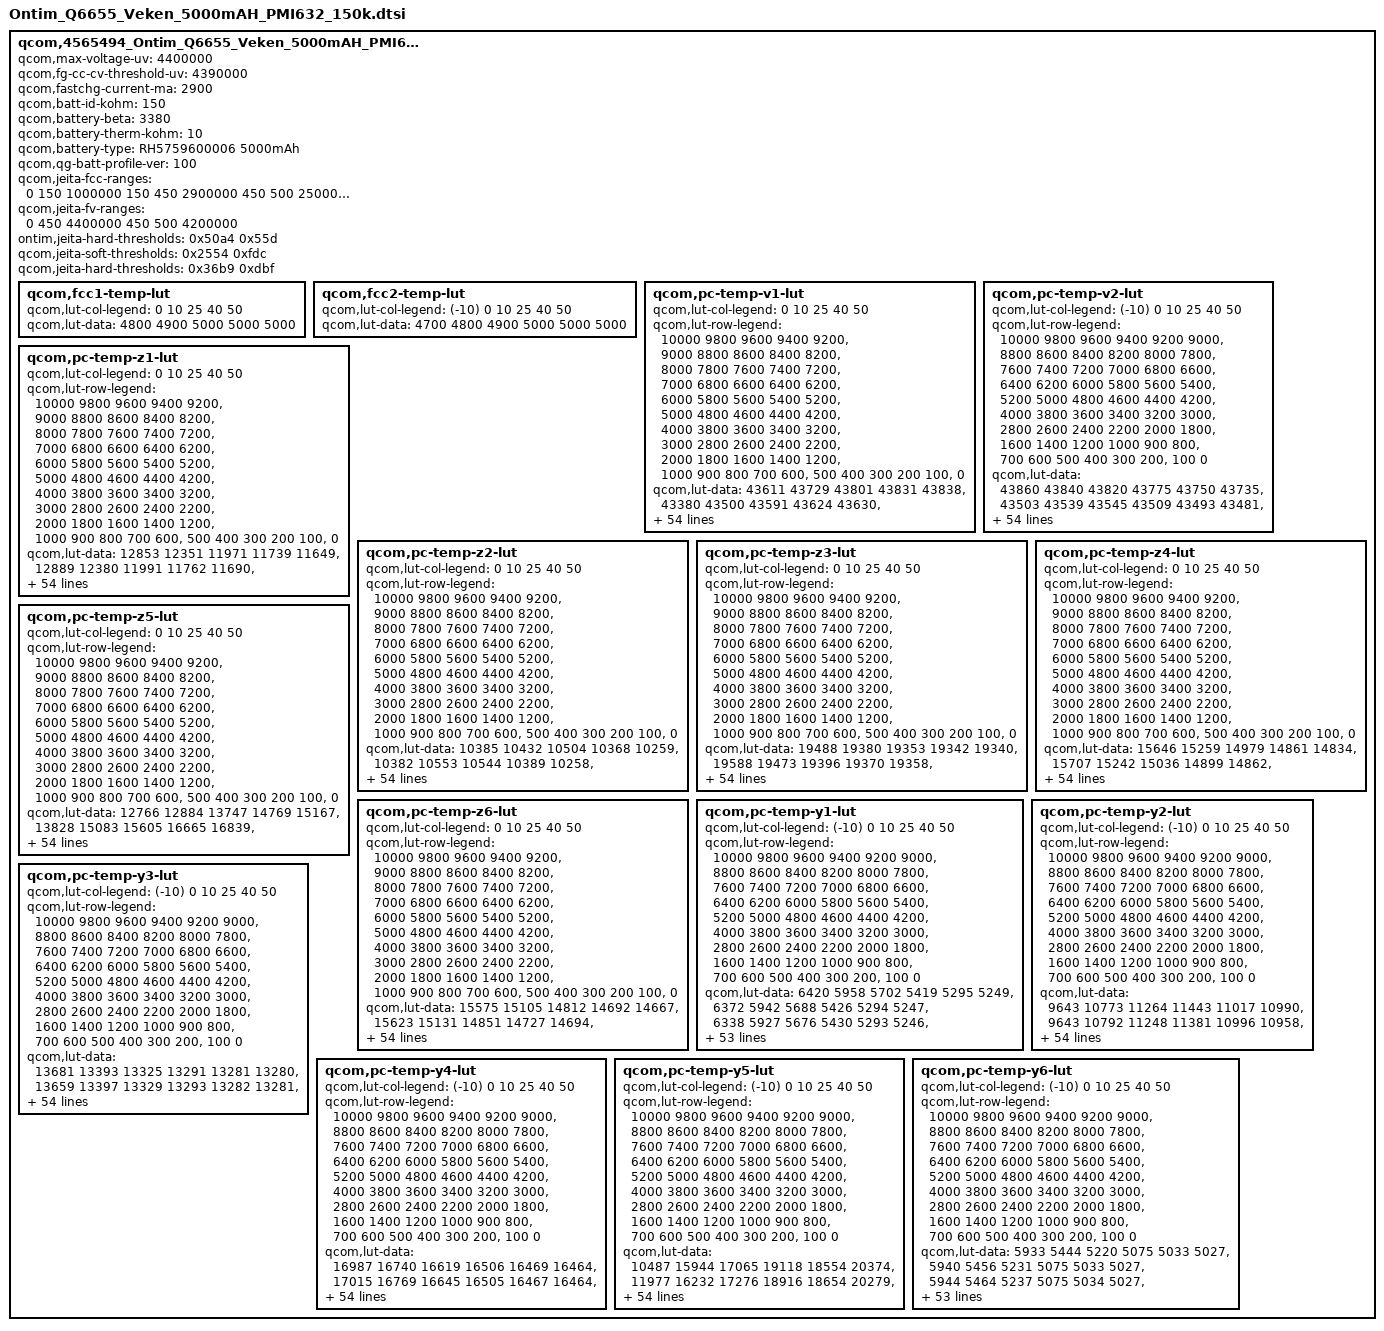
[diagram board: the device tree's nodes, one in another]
qcom,4565494_Ontim_Q6655_Veken_5000mAH_PMI632 {
    /* 4565494_Ontim_Q6655_Veken_5000mAH_PMI632_averaged_MasterSlave_May9th2020 */
    qcom,max-voltage-uv = <4400000>;
    qcom,fg-cc-cv-threshold-uv = <4390000>;
    qcom,fastchg-current-ma = <2900>;
    qcom,batt-id-kohm = <150>;
    qcom,battery-beta = <3380>;
    qcom,battery-therm-kohm = <10>;
    qcom,battery-type = "RH5759600006 5000mAh";
    qcom,qg-batt-profile-ver = <100>;

	qcom,jeita-fcc-ranges = <0     150   1000000
							 150   450   2900000
							 450   500   2500000>;
	
	qcom,jeita-fv-ranges = <0    450   4400000
							450  500   4200000>;

	/* ontim config jeita for dual 85 test begin */
	/* COLD = -20 DegC, HOT = 85 DegC */
	ontim,jeita-hard-thresholds = <0x50a4 0x55d>;
	/* ontim config jeita for dual 85 test end */

	/* COOL = 15 DegC, WARM = 45 DegC */
	qcom,jeita-soft-thresholds = <0x2554 0xfdc>;
	/* COLD = 0 DegC, HOT = 50 DegC */
	qcom,jeita-hard-thresholds = <0x36b9 0xdbf>;

	qcom,fcc1-temp-lut {
		qcom,lut-col-legend = <0 10 25 40 50>;
		qcom,lut-data = <4800 4900 5000 5000 5000>;
	};

	qcom,fcc2-temp-lut {
		qcom,lut-col-legend = <(-10) 0 10 25 40 50>;
		qcom,lut-data = <4700 4800 4900 5000 5000 5000>;
	};

	qcom,pc-temp-v1-lut {
		qcom,lut-col-legend = <0 10 25 40 50>;
		qcom,lut-row-legend = <10000 9800 9600 9400 9200>,
			<9000 8800 8600 8400 8200>,
			<8000 7800 7600 7400 7200>,
			<7000 6800 6600 6400 6200>,
			<6000 5800 5600 5400 5200>,
			<5000 4800 4600 4400 4200>,
			<4000 3800 3600 3400 3200>,
			<3000 2800 2600 2400 2200>,
			<2000 1800 1600 1400 1200>,
			<1000 900 800 700 600>,
			<500 400 300 200 100>,
			<0>;
		qcom,lut-data = <43611 43729 43801 43831 43838>,
			<43380 43500 43591 43624 43630>,
			<43143 43270 43369 43412 43421>,
			<42904 43039 43143 43195 43208>,
			<42669 42807 42911 42970 42984>,
			<42434 42572 42675 42736 42752>,
			<42203 42338 42440 42503 42520>,
			<41978 42105 42203 42265 42286>,
			<41756 41877 41971 42031 42053>,
			<41539 41652 41742 41800 41824>,
			<41325 41434 41517 41572 41596>,
			<41117 41222 41299 41352 41374>,
			<40917 41016 41087 41136 41154>,
			<40723 40818 40883 40928 40942>,
			<40535 40625 40682 40725 40739>,
			<40350 40440 40490 40529 40545>,
			<40173 40262 40308 40343 40358>,
			<40011 40092 40134 40164 40178>,
			<39861 39937 39969 39994 40005>,
			<39714 39789 39824 39843 39849>,
			<39571 39615 39665 39691 39694>,
			<39426 39405 39419 39480 39490>,
			<39257 39193 39119 39191 39212>,
			<39050 38983 38929 38974 38992>,
			<38860 38782 38823 38857 38872>,
			<38710 38661 38737 38765 38778>,
			<38582 38593 38650 38668 38673>,
			<38496 38537 38570 38572 38565>,
			<38438 38477 38492 38481 38469>,
			<38393 38417 38415 38394 38387>,
			<38353 38363 38345 38316 38314>,
			<38319 38312 38282 38247 38243>,
			<38287 38265 38225 38189 38177>,
			<38258 38223 38174 38132 38112>,
			<38231 38185 38131 38079 38051>,
			<38202 38147 38090 38027 37991>,
			<38173 38114 38051 37976 37930>,
			<38136 38076 38011 37926 37870>,
			<38077 38017 37954 37859 37795>,
			<37995 37927 37864 37764 37695>,
			<37896 37824 37758 37654 37583>,
			<37770 37703 37643 37541 37466>,
			<37626 37563 37510 37413 37335>,
			<37458 37394 37345 37252 37167>,
			<37304 37241 37195 37111 37034>,
			<37207 37133 37092 37027 36964>,
			<37165 37103 37065 36996 36934>,
			<37130 37084 37042 36978 36917>,
			<37098 37057 37025 36957 36896>,
			<37055 37017 36986 36912 36843>,
			<36927 36845 36795 36685 36592>,
			<36523 36408 36365 36257 36160>,
			<35952 35824 35794 35689 35593>,
			<35000 35000 35000 35000 35000>, // 2
			<34500 34500 34500 34500 34500>, // 1
			<34000 34000 34000 34000 34000>; // 0
	};

	qcom,pc-temp-v2-lut {
		qcom,lut-col-legend = <(-10) 0 10 25 40 50>;
		qcom,lut-row-legend = <10000 9800 9600 9400 9200 9000>,
			<8800 8600 8400 8200 8000 7800>,
			<7600 7400 7200 7000 6800 6600>,
			<6400 6200 6000 5800 5600 5400>,
			<5200 5000 4800 4600 4400 4200>,
			<4000 3800 3600 3400 3200 3000>,
			<2800 2600 2400 2200 2000 1800>,
			<1600 1400 1200 1000 900 800>,
			<700 600 500 400 300 200>,
			<100 0>;
		qcom,lut-data = <43860 43840 43820 43775 43750 43735>,
			<43503 43539 43545 43509 43493 43481>,
			<43180 43256 43280 43253 43243 43233>,
			<42897 42995 43029 43006 43001 42994>,
			<42652 42753 42791 42771 42769 42763>,
			<42417 42515 42553 42537 42536 42532>,
			<42179 42270 42312 42301 42300 42298>,
			<41943 42026 42070 42064 42065 42063>,
			<41702 41790 41833 41832 41833 41832>,
			<41449 41560 41599 41603 41605 41604>,
			<41218 41335 41371 41379 41380 41379>,
			<41041 41112 41151 41160 41160 41160>,
			<40885 40895 40937 40946 40945 40944>,
			<40679 40698 40731 40740 40739 40738>,
			<40385 40521 40528 40539 40540 40536>,
			<40081 40338 40336 40346 40349 40344>,
			<39819 40138 40166 40162 40165 40161>,
			<39572 39927 39999 39985 39988 39987>,
			<39348 39701 39801 39820 39822 39821>,
			<39142 39453 39575 39672 39672 39670>,
			<38949 39217 39351 39500 39500 39499>,
			<38753 39012 39134 39257 39265 39269>,
			<38565 38824 38930 39001 39019 39026>,
			<38423 38655 38760 38815 38836 38844>,
			<38320 38500 38614 38667 38688 38697>,
			<38237 38361 38484 38541 38562 38570>,
			<38168 38228 38365 38429 38453 38459>,
			<38109 38111 38256 38331 38357 38360>,
			<38054 38035 38155 38242 38268 38269>,
			<38002 37983 38059 38161 38187 38184>,
			<37951 37939 37981 38087 38114 38108>,
			<37899 37896 37919 38015 38048 38043>,
			<37845 37855 37867 37948 37987 37981>,
			<37791 37812 37823 37887 37922 37913>,
			<37738 37767 37787 37832 37856 37839>,
			<37684 37718 37749 37776 37781 37756>,
			<37625 37666 37709 37715 37691 37656>,
			<37562 37609 37666 37652 37595 37548>,
			<37493 37540 37606 37578 37509 37456>,
			<37416 37459 37526 37494 37428 37373>,
			<37332 37363 37429 37403 37341 37287>,
			<37239 37245 37297 37304 37244 37192>,
			<37137 37113 37151 37189 37132 37082>,
			<37039 36976 37000 37044 36989 36934>,
			<36947 36850 36857 36918 36882 36830>,
			<36861 36749 36757 36859 36838 36787>,
			<36818 36707 36716 36845 36829 36777>,
			<36775 36666 36674 36827 36814 36763>,
			<36731 36621 36622 36803 36789 36736>,
			<36678 36551 36534 36744 36718 36656>,
			<36600 36407 36347 36543 36467 36365>,
			<36414 36050 35928 36075 35978 35872>,
			<36011 35414 35293 35463 35347 35233>,
			<35000 35000 35000 35000 35000 35000>, // 2
			<34500 34500 34500 34500 34500 34500>, // 1
			<33000 33000 33000 33000 33000 33000>; // 0
	};

	qcom,pc-temp-z1-lut {
		qcom,lut-col-legend = <0 10 25 40 50>;
		qcom,lut-row-legend = <10000 9800 9600 9400 9200>,
			<9000 8800 8600 8400 8200>,
			<8000 7800 7600 7400 7200>,
			<7000 6800 6600 6400 6200>,
			<6000 5800 5600 5400 5200>,
			<5000 4800 4600 4400 4200>,
			<4000 3800 3600 3400 3200>,
			<3000 2800 2600 2400 2200>,
			<2000 1800 1600 1400 1200>,
			<1000 900 800 700 600>,
			<500 400 300 200 100>,
			<0>;
		qcom,lut-data = <12853 12351 11971 11739 11649>,
			<12889 12380 11991 11762 11690>,
			<12906 12390 12000 11769 11696>,
			<12919 12387 12000 11771 11698>,
			<12917 12384 11997 11768 11699>,
			<12897 12380 11994 11765 11699>,
			<12879 12372 11988 11763 11700>,
			<12873 12364 11981 11761 11701>,
			<12870 12354 11974 11759 11702>,
			<12869 12344 11968 11760 11705>,
			<12869 12338 11963 11761 11708>,
			<12867 12334 11963 11761 11710>,
			<12855 12331 11964 11761 11710>,
			<12834 12329 11964 11762 11710>,
			<12818 12328 11966 11762 11710>,
			<12807 12327 11967 11762 11711>,
			<12799 12321 11968 11763 11712>,
			<12795 12317 11968 11764 11712>,
			<12791 12319 11968 11766 11714>,
			<12789 12323 11971 11767 11715>,
			<12791 12326 11974 11768 11716>,
			<12795 12333 11974 11769 11717>,
			<12795 12338 11974 11770 11718>,
			<12793 12341 11975 11771 11719>,
			<12793 12345 11980 11773 11721>,
			<12801 12346 11986 11777 11724>,
			<12816 12348 11988 11780 11727>,
			<12822 12351 11991 11783 11730>,
			<12815 12357 11993 11786 11733>,
			<12808 12365 11997 11790 11736>,
			<12808 12367 12002 11794 11739>,
			<12810 12364 12006 11797 11743>,
			<12813 12360 12009 11801 11746>,
			<12818 12363 12013 11805 11749>,
			<12825 12373 12016 11809 11752>,
			<12832 12379 12019 11813 11755>,
			<12839 12381 12022 11817 11758>,
			<12847 12383 12026 11820 11761>,
			<12859 12386 12031 11824 11764>,
			<12875 12392 12040 11830 11767>,
			<12890 12401 12049 11835 11771>,
			<12915 12420 12057 11838 11774>,
			<12927 12433 12063 11842 11778>,
			<12921 12435 12065 11847 11781>,
			<12941 12441 12075 11854 11785>,
			<12929 12435 12091 11856 11787>,
			<12954 12443 12085 11855 11786>,
			<12946 12431 12082 11855 11787>,
			<12953 12442 12087 11861 11788>,
			<12946 12434 12082 11863 11793>,
			<12937 12466 12091 11874 11799>,
			<12965 12474 12118 11879 11807>,
			<13009 12477 12124 11890 11815>,
			<12995 12493 12131 11906 11830>,
			<12995 12493 12131 11906 11830>,
			<12995 12493 12131 11906 11830>;
	};

	qcom,pc-temp-z2-lut {
		qcom,lut-col-legend = <0 10 25 40 50>;
		qcom,lut-row-legend = <10000 9800 9600 9400 9200>,
			<9000 8800 8600 8400 8200>,
			<8000 7800 7600 7400 7200>,
			<7000 6800 6600 6400 6200>,
			<6000 5800 5600 5400 5200>,
			<5000 4800 4600 4400 4200>,
			<4000 3800 3600 3400 3200>,
			<3000 2800 2600 2400 2200>,
			<2000 1800 1600 1400 1200>,
			<1000 900 800 700 600>,
			<500 400 300 200 100>,
			<0>;
		qcom,lut-data = <10385 10432 10504 10368 10259>,
			<10382 10553 10544 10389 10258>,
			<10349 10588 10591 10416 10273>,
			<10307 10552 10608 10438 10279>,
			<10274 10503 10583 10427 10285>,
			<10243 10462 10547 10396 10302>,
			<10219 10423 10518 10370 10307>,
			<10201 10396 10488 10347 10280>,
			<10186 10379 10462 10331 10253>,
			<10177 10367 10440 10321 10234>,
			<10169 10358 10423 10309 10194>,
			<10165 10350 10417 10304 10174>,
			<10165 10346 10413 10290 10166>,
			<10167 10356 10414 10280 10163>,
			<10170 10376 10421 10279 10150>,
			<10179 10397 10433 10278 10127>,
			<10192 10425 10448 10277 10127>,
			<10210 10452 10467 10276 10138>,
			<10236 10471 10483 10275 10152>,
			<10263 10490 10493 10263 10173>,
			<10288 10518 10506 10252 10206>,
			<10314 10565 10567 10311 10264>,
			<10337 10596 10678 10511 10379>,
			<10361 10580 10700 10615 10441>,
			<10378 10544 10568 10495 10394>,
			<10387 10527 10452 10345 10328>,
			<10393 10522 10475 10371 10363>,
			<10398 10518 10539 10517 10538>,
			<10404 10524 10580 10583 10626>,
			<10409 10539 10609 10548 10488>,
			<10415 10550 10623 10492 10294>,
			<10421 10556 10615 10437 10201>,
			<10427 10562 10599 10376 10137>,
			<10435 10569 10595 10351 10118>,
			<10443 10577 10596 10346 10143>,
			<10452 10587 10599 10343 10186>,
			<10460 10598 10613 10352 10235>,
			<10470 10611 10642 10383 10297>,
			<10482 10629 10674 10423 10347>,
			<10495 10652 10717 10506 10391>,
			<10508 10665 10744 10570 10418>,
			<10520 10669 10747 10573 10419>,
			<10535 10674 10749 10568 10417>,
			<10555 10689 10750 10584 10497>,
			<10786 10807 10785 10567 10509>,
			<10602 10885 10806 10506 10407>,
			<10590 10891 10779 10506 10383>,
			<10558 10979 10763 10511 10419>,
			<10496 11225 10718 10532 10439>,
			<10451 11321 10744 10632 10538>,
			<10327 11266 10841 10556 10445>,
			<10318 10955 10819 10392 10239>,
			<10115 10811 10708 10328 10172>,
			<9950 10578 10687 10292 10116>,
			<9950 10578 10687 10292 10116>,
			<9950 10578 10687 10292 10116>;
	};

	qcom,pc-temp-z3-lut {
		qcom,lut-col-legend = <0 10 25 40 50>;
		qcom,lut-row-legend = <10000 9800 9600 9400 9200>,
			<9000 8800 8600 8400 8200>,
			<8000 7800 7600 7400 7200>,
			<7000 6800 6600 6400 6200>,
			<6000 5800 5600 5400 5200>,
			<5000 4800 4600 4400 4200>,
			<4000 3800 3600 3400 3200>,
			<3000 2800 2600 2400 2200>,
			<2000 1800 1600 1400 1200>,
			<1000 900 800 700 600>,
			<500 400 300 200 100>,
			<0>;
		qcom,lut-data = <19488 19380 19353 19342 19340>,
			<19588 19473 19396 19370 19358>,
			<19649 19519 19422 19384 19370>,
			<19690 19534 19436 19392 19379>,
			<19707 19542 19444 19400 19388>,
			<19717 19545 19449 19406 19396>,
			<19721 19547 19451 19410 19400>,
			<19719 19548 19451 19414 19402>,
			<19715 19548 19452 19416 19404>,
			<19711 19548 19450 19416 19403>,
			<19708 19546 19448 19414 19401>,
			<19703 19539 19443 19411 19399>,
			<19698 19531 19433 19404 19395>,
			<19693 19525 19427 19398 19391>,
			<19686 19520 19423 19394 19387>,
			<19680 19515 19420 19390 19382>,
			<19672 19509 19417 19386 19378>,
			<19660 19504 19414 19384 19374>,
			<19642 19498 19410 19380 19371>,
			<19632 19491 19405 19373 19366>,
			<19630 19492 19402 19365 19361>,
			<19629 19506 19409 19366 19361>,
			<19632 19518 19425 19377 19365>,
			<19647 19517 19429 19382 19367>,
			<19658 19514 19410 19367 19356>,
			<19658 19511 19393 19348 19342>,
			<19655 19502 19393 19352 19351>,
			<19652 19495 19395 19375 19396>,
			<19648 19495 19399 19392 19419>,
			<19642 19496 19414 19402 19411>,
			<19636 19497 19427 19408 19399>,
			<19630 19500 19429 19406 19391>,
			<19624 19502 19430 19397 19384>,
			<19619 19502 19430 19389 19377>,
			<19614 19500 19424 19382 19369>,
			<19610 19498 19417 19375 19362>,
			<19605 19494 19411 19368 19356>,
			<19600 19489 19404 19361 19351>,
			<19595 19485 19400 19359 19349>,
			<19588 19481 19398 19359 19347>,
			<19581 19476 19396 19358 19346>,
			<19572 19472 19393 19358 19348>,
			<19562 19467 19391 19358 19353>,
			<19550 19460 19387 19358 19360>,
			<19495 19435 19378 19357 19360>,
			<19337 19422 19372 19345 19344>,
			<19325 19408 19367 19344 19342>,
			<19317 19333 19366 19335 19330>,
			<19308 19302 19351 19333 19326>,
			<19302 19293 19346 19325 19318>,
			<19287 19302 19341 19340 19333>,
			<19311 19322 19352 19358 19352>,
			<19322 19319 19350 19356 19349>,
			<19340 19328 19342 19351 19349>,
			<19340 19328 19342 19351 19349>,
			<19340 19328 19342 19351 19349>;
	};

	qcom,pc-temp-z4-lut {
		qcom,lut-col-legend = <0 10 25 40 50>;
		qcom,lut-row-legend = <10000 9800 9600 9400 9200>,
			<9000 8800 8600 8400 8200>,
			<8000 7800 7600 7400 7200>,
			<7000 6800 6600 6400 6200>,
			<6000 5800 5600 5400 5200>,
			<5000 4800 4600 4400 4200>,
			<4000 3800 3600 3400 3200>,
			<3000 2800 2600 2400 2200>,
			<2000 1800 1600 1400 1200>,
			<1000 900 800 700 600>,
			<500 400 300 200 100>,
			<0>;
		qcom,lut-data = <15646 15259 14979 14861 14834>,
			<15707 15242 15036 14899 14862>,
			<15603 15207 14996 14882 14852>,
			<15442 15130 14954 14857 14836>,
			<15325 15037 14911 14835 14819>,
			<15223 14974 14869 14811 14799>,
			<15139 14925 14836 14790 14781>,
			<15074 14885 14809 14770 14765>,
			<15020 14849 14786 14752 14750>,
			<14974 14820 14765 14735 14735>,
			<14933 14798 14748 14721 14721>,
			<14898 14782 14736 14711 14712>,
			<14869 14767 14726 14704 14706>,
			<14843 14752 14719 14699 14701>,
			<14824 14738 14713 14694 14697>,
			<14809 14730 14708 14690 14694>,
			<14797 14725 14703 14686 14690>,
			<14786 14721 14699 14681 14686>,
			<14777 14716 14695 14679 14682>,
			<14768 14710 14691 14677 14678>,
			<14755 14711 14689 14676 14674>,
			<14743 14728 14721 14692 14688>,
			<14745 14753 14798 14765 14762>,
			<14771 14791 14830 14811 14808>,
			<14801 14840 14839 14820 14810>,
			<14825 14853 14842 14825 14810>,
			<14847 14840 14835 14814 14794>,
			<14852 14823 14815 14773 14731>,
			<14844 14808 14794 14739 14695>,
			<14832 14792 14766 14716 14692>,
			<14820 14778 14743 14700 14690>,
			<14808 14764 14729 14693 14686>,
			<14795 14751 14719 14689 14681>,
			<14783 14743 14715 14688 14679>,
			<14772 14736 14713 14688 14678>,
			<14760 14730 14712 14688 14677>,
			<14748 14724 14711 14688 14677>,
			<14737 14719 14709 14688 14678>,
			<14730 14718 14710 14689 14680>,
			<14724 14718 14714 14698 14693>,
			<14719 14717 14718 14706 14703>,
			<14716 14708 14712 14702 14698>,
			<14710 14697 14702 14695 14689>,
			<14700 14690 14697 14694 14691>,
			<14699 14672 14681 14684 14683>,
			<14836 14658 14663 14668 14664>,
			<14845 14662 14656 14662 14658>,
			<14849 14738 14644 14654 14653>,
			<14853 14763 14643 14635 14635>,
			<14853 14769 14641 14630 14626>,
			<14863 14761 14659 14647 14655>,
			<14862 14755 14664 14649 14660>,
			<14870 14766 14670 14656 14668>,
			<14878 14770 14681 14664 14671>,
			<14878 14770 14681 14664 14671>,
			<14878 14770 14681 14664 14671>;
	};

	qcom,pc-temp-z5-lut {
		qcom,lut-col-legend = <0 10 25 40 50>;
		qcom,lut-row-legend = <10000 9800 9600 9400 9200>,
			<9000 8800 8600 8400 8200>,
			<8000 7800 7600 7400 7200>,
			<7000 6800 6600 6400 6200>,
			<6000 5800 5600 5400 5200>,
			<5000 4800 4600 4400 4200>,
			<4000 3800 3600 3400 3200>,
			<3000 2800 2600 2400 2200>,
			<2000 1800 1600 1400 1200>,
			<1000 900 800 700 600>,
			<500 400 300 200 100>,
			<0>;
		qcom,lut-data = <12766 12884 13747 14769 15167>,
			<13828 15083 15605 16665 16839>,
			<14589 16392 16712 17614 17951>,
			<15230 16968 17554 18282 18784>,
			<15818 17397 18208 19022 19886>,
			<16349 17931 18782 19726 21091>,
			<16847 18500 19394 20589 22142>,
			<17312 19176 20008 21711 23102>,
			<17779 20175 20705 22858 24038>,
			<18346 21233 21692 24056 24936>,
			<19096 21892 22473 25198 25815>,
			<19953 22346 22649 25596 26740>,
			<20892 22900 22720 25668 27884>,
			<21928 23955 22891 25774 28652>,
			<22927 25296 23591 26160 28736>,
			<24075 26363 24535 26818 28712>,
			<24949 27273 25408 27720 28966>,
			<25101 28026 26341 29167 30027>,
			<25096 28617 27191 29924 31112>,
			<25151 29368 27801 28884 31877>,
			<26824 32058 28679 27406 32462>,
			<30546 44017 33919 28117 32453>,
			<36678 53303 43780 32062 31728>,
			<50036 50853 45784 34082 30495>,
			<59250 44450 34171 27140 24758>,
			<57985 39345 23247 18414 17715>,
			<54265 33610 21487 17763 18942>,
			<50699 29640 20595 19250 27784>,
			<47025 29334 20685 21346 32314>,
			<43698 29292 23448 25699 31015>,
			<41482 29489 27237 29835 29451>,
			<39719 31551 31098 30828 29490>,
			<38656 34424 35166 31304 30134>,
			<38012 36900 37476 31580 30473>,
			<37607 39530 38964 31852 30465>,
			<37698 41159 39669 32033 30372>,
			<38553 42310 39012 31566 30165>,
			<39578 43096 37446 30281 29708>,
			<40673 42961 36079 29444 29029>,
			<41776 42203 34805 28919 27114>,
			<41731 41410 33502 28314 25578>,
			<38697 39880 32084 27229 25886>,
			<36611 38055 30792 26268 27035>,
			<35798 36418 29780 26979 31392>,
			<29108 35321 30482 27770 32987>,
			<13232 34617 31580 24304 25487>,
			<12816 27912 29518 24010 24230>,
			<12561 14534 31732 22056 20707>,
			<12293 12861 24898 26301 23886>,
			<12179 12558 24635 25720 24665>,
			<12015 12972 20238 27986 25734>,
			<12316 13690 20220 26371 23564>,
			<12309 13272 18716 22106 19316>,
			<12769 13619 16863 18563 17113>,
			<12769 13619 16863 18563 17113>,
			<12769 13619 16863 18563 17113>;
	};

	qcom,pc-temp-z6-lut {
		qcom,lut-col-legend = <0 10 25 40 50>;
		qcom,lut-row-legend = <10000 9800 9600 9400 9200>,
			<9000 8800 8600 8400 8200>,
			<8000 7800 7600 7400 7200>,
			<7000 6800 6600 6400 6200>,
			<6000 5800 5600 5400 5200>,
			<5000 4800 4600 4400 4200>,
			<4000 3800 3600 3400 3200>,
			<3000 2800 2600 2400 2200>,
			<2000 1800 1600 1400 1200>,
			<1000 900 800 700 600>,
			<500 400 300 200 100>,
			<0>;
		qcom,lut-data = <15575 15105 14812 14692 14667>,
			<15623 15131 14851 14727 14694>,
			<15583 15135 14848 14727 14697>,
			<15517 15103 14842 14725 14697>,
			<15462 15054 14827 14720 14696>,
			<15407 15020 14807 14712 14692>,
			<15358 14992 14792 14705 14687>,
			<15319 14968 14778 14699 14682>,
			<15284 14948 14766 14692 14676>,
			<15254 14930 14756 14685 14671>,
			<15226 14914 14746 14679 14665>,
			<15201 14900 14736 14672 14659>,
			<15180 14887 14727 14666 14655>,
			<15160 14875 14720 14660 14650>,
			<15143 14865 14716 14655 14646>,
			<15130 14858 14712 14651 14641>,
			<15117 14852 14708 14647 14637>,
			<15103 14848 14704 14644 14633>,
			<15088 14843 14701 14641 14630>,
			<15078 14838 14698 14636 14625>,
			<15073 14839 14695 14631 14621>,
			<15070 14853 14714 14640 14627>,
			<15072 14872 14757 14678 14661>,
			<15092 14890 14770 14699 14682>,
			<15113 14910 14766 14695 14678>,
			<15125 14914 14760 14689 14672>,
			<15135 14906 14755 14685 14669>,
			<15137 14896 14750 14681 14668>,
			<15132 14890 14746 14678 14665>,
			<15125 14886 14743 14675 14660>,
			<15119 14882 14740 14671 14654>,
			<15111 14878 14737 14667 14649>,
			<15104 14875 14734 14662 14643>,
			<15098 14872 14731 14658 14639>,
			<15094 14870 14729 14654 14634>,
			<15089 14868 14726 14650 14630>,
			<15084 14864 14723 14647 14627>,
			<15081 14862 14719 14643 14624>,
			<15080 14862 14719 14642 14624>,
			<15080 14864 14721 14647 14628>,
			<15080 14864 14723 14650 14633>,
			<15082 14861 14721 14649 14632>,
			<15083 14859 14718 14647 14631>,
			<15083 14857 14716 14647 14635>,
			<15063 14846 14708 14643 14633>,
			<15050 14837 14699 14631 14617>,
			<15049 14833 14694 14628 14613>,
			<15049 14828 14689 14620 14605>,
			<15047 14824 14682 14611 14595>,
			<15049 14826 14680 14605 14587>,
			<15056 14833 14689 14621 14608>,
			<15074 14848 14701 14635 14624>,
			<15095 14860 14707 14639 14628>,
			<15125 14880 14714 14643 14633>,
			<15125 14880 14714 14643 14633>,
			<15125 14880 14714 14643 14633>;
	};

	qcom,pc-temp-y1-lut {
		qcom,lut-col-legend = <(-10) 0 10 25 40 50>;
		qcom,lut-row-legend = <10000 9800 9600 9400 9200 9000>,
			<8800 8600 8400 8200 8000 7800>,
			<7600 7400 7200 7000 6800 6600>,
			<6400 6200 6000 5800 5600 5400>,
			<5200 5000 4800 4600 4400 4200>,
			<4000 3800 3600 3400 3200 3000>,
			<2800 2600 2400 2200 2000 1800>,
			<1600 1400 1200 1000 900 800>,
			<700 600 500 400 300 200>,
			<100 0>;
		qcom,lut-data = <6420 5958 5702 5419 5295 5249>,
			<6372 5942 5688 5426 5294 5247>,
			<6338 5927 5676 5430 5293 5246>,
			<6315 5915 5666 5431 5291 5244>,
			<6303 5907 5659 5431 5290 5242>,
			<6299 5902 5656 5430 5288 5241>,
			<6313 5901 5657 5427 5286 5241>,
			<6336 5903 5660 5423 5284 5240>,
			<6339 5902 5660 5420 5282 5240>,
			<6322 5899 5657 5416 5281 5239>,
			<6307 5897 5656 5414 5280 5238>,
			<6313 5898 5655 5413 5279 5237>,
			<6326 5901 5654 5413 5279 5237>,
			<6330 5904 5652 5413 5278 5237>,
			<6330 5911 5646 5414 5278 5238>,
			<6330 5915 5643 5414 5278 5238>,
			<6325 5911 5650 5414 5278 5239>,
			<6316 5906 5661 5414 5278 5240>,
			<6312 5906 5665 5414 5279 5240>,
			<6307 5911 5666 5415 5280 5241>,
			<6303 5914 5667 5416 5281 5241>,
			<6306 5915 5665 5419 5281 5242>,
			<6311 5916 5662 5422 5282 5242>,
			<6314 5917 5661 5425 5283 5243>,
			<6311 5926 5663 5428 5285 5245>,
			<6307 5932 5665 5431 5287 5246>,
			<6305 5925 5671 5433 5290 5247>,
			<6304 5916 5679 5436 5292 5249>,
			<6303 5914 5678 5440 5295 5251>,
			<6317 5915 5669 5446 5297 5253>,
			<6333 5916 5665 5451 5300 5256>,
			<6331 5922 5674 5454 5303 5258>,
			<6316 5929 5687 5455 5306 5260>,
			<6308 5930 5690 5456 5309 5262>,
			<6321 5928 5690 5458 5311 5264>,
			<6335 5927 5690 5460 5313 5265>,
			<6335 5927 5694 5461 5315 5267>,
			<6330 5928 5698 5462 5316 5269>,
			<6326 5927 5698 5464 5318 5271>,
			<6321 5925 5696 5467 5321 5272>,
			<6316 5924 5694 5471 5323 5273>,
			<6314 5921 5690 5480 5324 5274>,
			<6308 5919 5687 5487 5326 5276>,
			<6298 5923 5686 5487 5329 5279>,
			<6289 5925 5691 5492 5335 5283>,
			<6327 5953 5691 5499 5338 5284>,
			<6342 5946 5702 5498 5336 5284>,
			<6341 5956 5704 5495 5336 5285>,
			<6330 5941 5713 5494 5336 5285>,
			<6364 5971 5706 5496 5337 5285>,
			<6355 5947 5701 5497 5337 5287>,
			<6440 5983 5714 5507 5343 5292>,
			<6506 6043 5732 5526 5351 5298>,
			<6642 6161 5767 5537 5360 5305>,
			<6642 6161 5767 5537 5360 5305>,
			<6642 6161 5767 5537 5360 5305>;
	};

	qcom,pc-temp-y2-lut {
		qcom,lut-col-legend = <(-10) 0 10 25 40 50>;
		qcom,lut-row-legend = <10000 9800 9600 9400 9200 9000>,
			<8800 8600 8400 8200 8000 7800>,
			<7600 7400 7200 7000 6800 6600>,
			<6400 6200 6000 5800 5600 5400>,
			<5200 5000 4800 4600 4400 4200>,
			<4000 3800 3600 3400 3200 3000>,
			<2800 2600 2400 2200 2000 1800>,
			<1600 1400 1200 1000 900 800>,
			<700 600 500 400 300 200>,
			<100 0>;
		qcom,lut-data = <9643 10773 11264 11443 11017 10990>,
			<9643 10792 11248 11381 10996 10958>,
			<9796 10814 11227 11315 10972 10919>,
			<10061 10835 11201 11250 10949 10880>,
			<10284 10851 11174 11196 10927 10846>,
			<10424 10860 11145 11159 10907 10823>,
			<10486 10858 11112 11137 10889 10810>,
			<10528 10855 11077 11119 10872 10799>,
			<10571 10864 11052 11098 10856 10789>,
			<10614 10900 11028 11071 10841 10773>,
			<10657 10942 11018 11056 10831 10758>,
			<10707 10978 11036 11055 10825 10745>,
			<10759 11015 11074 11055 10822 10733>,
			<10762 11049 11118 11059 10831 10722>,
			<10509 11080 11179 11076 10856 10711>,
			<10274 11115 11242 11101 10883 10706>,
			<10120 11175 11311 11146 10905 10724>,
			<9818 11234 11372 11211 10932 10763>,
			<9712 11240 11399 11297 11002 10813>,
			<9700 11213 11416 11419 11159 10890>,
			<9692 11189 11422 11477 11239 10957>,
			<9686 11181 11416 11449 11205 11005>,
			<9682 11176 11403 11412 11157 11042>,
			<9679 11162 11392 11409 11144 11058>,
			<9676 11132 11381 11424 11146 11068>,
			<9674 11092 11377 11441 11163 11080>,
			<9672 10931 11383 11463 11200 11116>,
			<9671 10683 11389 11492 11241 11163>,
			<9670 10543 11397 11528 11265 11194>,
			<9669 10438 11424 11577 11291 11222>,
			<9667 10370 11438 11607 11313 11244>,
			<9666 10336 11426 11621 11327 11280>,
			<9665 10293 11405 11630 11336 11318>,
			<9664 10187 11383 11625 11350 11325>,
			<9664 9890 11355 11603 11391 11310>,
			<9663 9699 11320 11585 11410 11297>,
			<9663 9686 11273 11575 11381 11282>,
			<9662 9678 11212 11564 11344 11258>,
			<9662 9673 11139 11544 11338 11228>,
			<9662 9669 11041 11509 11349 11185>,
			<9662 9666 10906 11474 11354 11165>,
			<9662 9664 10529 11439 11344 11200>,
			<9662 9663 10251 11411 11326 11224>,
			<9661 9662 10175 11397 11273 11126>,
			<9661 9661 9863 11297 11162 10948>,
			<9660 9660 9770 11285 11056 10904>,
			<9659 9660 9729 11292 11084 10853>,
			<9659 9659 9697 11296 11113 10915>,
			<9658 9658 9682 11289 11135 10936>,
			<9656 9658 9675 11297 11151 10937>,
			<9654 9656 9669 11232 11062 10840>,
			<9651 9654 9663 11113 10981 10756>,
			<9649 9650 9658 11026 10882 10683>,
			<9649 9650 9655 10932 10741 10530>,
			<9649 9650 9655 10932 10741 10530>,
			<9649 9650 9655 10932 10741 10530>;
	};

	qcom,pc-temp-y3-lut {
		qcom,lut-col-legend = <(-10) 0 10 25 40 50>;
		qcom,lut-row-legend = <10000 9800 9600 9400 9200 9000>,
			<8800 8600 8400 8200 8000 7800>,
			<7600 7400 7200 7000 6800 6600>,
			<6400 6200 6000 5800 5600 5400>,
			<5200 5000 4800 4600 4400 4200>,
			<4000 3800 3600 3400 3200 3000>,
			<2800 2600 2400 2200 2000 1800>,
			<1600 1400 1200 1000 900 800>,
			<700 600 500 400 300 200>,
			<100 0>;
		qcom,lut-data = <13681 13393 13325 13291 13281 13280>,
			<13659 13397 13329 13293 13282 13281>,
			<13632 13401 13333 13294 13283 13281>,
			<13605 13405 13337 13295 13284 13282>,
			<13581 13409 13340 13297 13285 13282>,
			<13565 13411 13343 13298 13285 13283>,
			<13557 13412 13345 13298 13285 13283>,
			<13550 13412 13346 13299 13285 13284>,
			<13539 13413 13346 13300 13286 13285>,
			<13516 13414 13347 13300 13287 13285>,
			<13498 13415 13347 13301 13287 13286>,
			<13491 13405 13348 13303 13288 13286>,
			<13486 13389 13349 13304 13288 13286>,
			<13483 13385 13348 13305 13289 13287>,
			<13488 13385 13342 13305 13292 13287>,
			<13491 13384 13337 13305 13294 13287>,
			<13484 13382 13336 13304 13294 13289>,
			<13475 13380 13336 13303 13293 13291>,
			<13469 13375 13334 13303 13294 13292>,
			<13465 13366 13330 13303 13294 13292>,
			<13461 13357 13325 13302 13295 13293>,
			<13453 13351 13322 13299 13291 13289>,
			<13443 13347 13318 13294 13285 13283>,
			<13439 13343 13316 13292 13282 13281>,
			<13442 13341 13314 13290 13281 13280>,
			<13448 13338 13312 13290 13280 13279>,
			<13459 13329 13311 13289 13280 13279>,
			<13477 13318 13309 13288 13280 13279>,
			<13500 13314 13308 13288 13280 13279>,
			<13531 13311 13307 13289 13279 13277>,
			<13569 13311 13306 13289 13279 13276>,
			<13607 13318 13306 13288 13279 13277>,
			<13647 13331 13306 13288 13280 13278>,
			<13689 13345 13306 13288 13280 13278>,
			<13734 13365 13308 13288 13280 13279>,
			<13780 13387 13310 13288 13280 13279>,
			<13823 13413 13312 13288 13280 13279>,
			<13865 13444 13316 13289 13280 13278>,
			<13902 13481 13319 13288 13280 13279>,
			<13935 13528 13321 13288 13281 13280>,
			<13965 13581 13325 13288 13282 13281>,
			<13992 13642 13333 13290 13282 13282>,
			<14019 13708 13341 13291 13282 13282>,
			<14054 13776 13349 13291 13280 13279>,
			<14104 13857 13366 13292 13280 13280>,
			<14177 13878 13368 13293 13284 13284>,
			<14193 13940 13391 13295 13289 13287>,
			<14299 14011 13429 13298 13291 13289>,
			<14445 14092 13475 13304 13293 13290>,
			<14695 14195 13542 13307 13293 13290>,
			<15314 14375 13627 13305 13288 13285>,
			<17344 14966 13752 13302 13288 13285>,
			<23409 18496 14060 13310 13292 13289>,
			<46631 34442 15297 13321 13298 13298>,
			<46631 34442 15297 13321 13298 13298>,
			<46631 34442 15297 13321 13298 13298>;
	};

	qcom,pc-temp-y4-lut {
		qcom,lut-col-legend = <(-10) 0 10 25 40 50>;
		qcom,lut-row-legend = <10000 9800 9600 9400 9200 9000>,
			<8800 8600 8400 8200 8000 7800>,
			<7600 7400 7200 7000 6800 6600>,
			<6400 6200 6000 5800 5600 5400>,
			<5200 5000 4800 4600 4400 4200>,
			<4000 3800 3600 3400 3200 3000>,
			<2800 2600 2400 2200 2000 1800>,
			<1600 1400 1200 1000 900 800>,
			<700 600 500 400 300 200>,
			<100 0>;
		qcom,lut-data = <16987 16740 16619 16506 16469 16464>,
			<17015 16769 16645 16505 16467 16464>,
			<17065 16817 16669 16505 16465 16463>,
			<17122 16869 16689 16504 16464 16462>,
			<17169 16911 16702 16504 16464 16461>,
			<17193 16928 16707 16504 16464 16461>,
			<17196 16925 16701 16504 16465 16461>,
			<17197 16920 16692 16504 16466 16461>,
			<17200 16916 16688 16504 16467 16461>,
			<17206 16911 16686 16507 16469 16462>,
			<17215 16908 16685 16509 16471 16463>,
			<17231 16927 16687 16512 16475 16465>,
			<17251 16961 16693 16515 16479 16468>,
			<17247 16979 16705 16521 16482 16472>,
			<17152 16992 16731 16530 16484 16476>,
			<17045 16998 16757 16541 16488 16481>,
			<16991 16981 16781 16557 16495 16485>,
			<16950 16942 16799 16576 16507 16490>,
			<16907 16896 16793 16603 16526 16502>,
			<16858 16828 16751 16640 16557 16528>,
			<16810 16765 16701 16657 16571 16541>,
			<16761 16719 16651 16606 16543 16521>,
			<16713 16679 16603 16532 16500 16489>,
			<16696 16641 16577 16504 16480 16474>,
			<16693 16602 16561 16489 16468 16465>,
			<16692 16576 16549 16484 16464 16461>,
			<16693 16563 16540 16485 16465 16462>,
			<16696 16553 16532 16487 16469 16463>,
			<16699 16555 16520 16490 16473 16467>,
			<16701 16571 16504 16495 16481 16475>,
			<16703 16585 16496 16499 16489 16484>,
			<16706 16589 16495 16502 16501 16495>,
			<16712 16594 16498 16504 16511 16504>,
			<16717 16605 16504 16505 16512 16507>,
			<16721 16627 16518 16505 16512 16509>,
			<16725 16647 16536 16505 16511 16510>,
			<16730 16660 16556 16501 16495 16496>,
			<16735 16672 16577 16495 16475 16478>,
			<16737 16679 16592 16493 16474 16477>,
			<16734 16685 16604 16492 16475 16480>,
			<16729 16687 16609 16492 16477 16485>,
			<16720 16672 16605 16502 16482 16491>,
			<16708 16652 16601 16509 16484 16494>,
			<16705 16643 16599 16504 16463 16461>,
			<16705 16643 16609 16500 16455 16451>,
			<16713 16632 16605 16491 16467 16473>,
			<16706 16642 16625 16506 16488 16500>,
			<16714 16661 16659 16527 16515 16532>,
			<16731 16684 16708 16557 16548 16564>,
			<16754 16718 16768 16583 16560 16571>,
			<16790 16752 16815 16573 16516 16502>,
			<17031 16738 16825 16534 16476 16477>,
			<17884 17436 16844 16552 16477 16477>,
			<26080 29635 17185 16587 16494 16482>,
			<26080 29635 17185 16587 16494 16482>,
			<26080 29635 17185 16587 16494 16482>;
	};

	qcom,pc-temp-y5-lut {
		qcom,lut-col-legend = <(-10) 0 10 25 40 50>;
		qcom,lut-row-legend = <10000 9800 9600 9400 9200 9000>,
			<8800 8600 8400 8200 8000 7800>,
			<7600 7400 7200 7000 6800 6600>,
			<6400 6200 6000 5800 5600 5400>,
			<5200 5000 4800 4600 4400 4200>,
			<4000 3800 3600 3400 3200 3000>,
			<2800 2600 2400 2200 2000 1800>,
			<1600 1400 1200 1000 900 800>,
			<700 600 500 400 300 200>,
			<100 0>;
		qcom,lut-data = <10487 15944 17065 19118 18554 20374>,
			<11977 16232 17276 18916 18654 20279>,
			<13496 16619 17621 18723 18655 20161>,
			<14925 17023 17996 18542 18582 20038>,
			<16149 17359 18297 18379 18459 19927>,
			<17049 17542 18419 18238 18310 19848>,
			<17721 17600 18408 17947 17858 19621>,
			<18214 17636 18376 17529 17225 19286>,
			<18245 17710 18260 17199 16905 19077>,
			<17759 17919 17841 16856 16721 18751>,
			<17376 18031 17448 16620 16507 18369>,
			<18472 17451 17192 16544 16046 17846>,
			<20718 16573 16936 16465 15578 17193>,
			<21577 16617 16626 16187 15641 16577>,
			<21269 17921 16181 15607 16239 15907>,
			<20860 19479 15964 15111 16581 15596>,
			<20105 21159 16875 14734 15944 15783>,
			<18598 22696 18582 14445 15065 16051>,
			<18070 23045 20077 14656 14957 16006>,
			<18019 23097 21627 15937 15109 15602>,
			<17955 23158 22803 17531 15390 15371>,
			<17097 23387 23592 19797 17306 17064>,
			<14996 23776 24147 21922 19652 19476>,
			<13789 24272 24367 22348 19941 19948>,
			<13246 25143 24465 22340 19751 19936>,
			<12905 25640 24456 22216 19473 19822>,
			<12834 21852 24283 21626 18862 19289>,
			<12797 15785 24039 20952 18184 18397>,
			<12793 14152 23889 21108 17865 17398>,
			<12930 13864 23834 22058 17527 16103>,
			<13130 13881 23687 22643 17385 15507>,
			<13256 14386 22879 22751 17637 15910>,
			<13353 15081 21846 22843 18143 16673>,
			<13490 15269 21372 23086 18910 17461>,
			<13782 14941 21034 23627 20228 18509>,
			<14100 14752 20910 23891 21300 19613>,
			<14266 14935 21131 23899 22086 20974>,
			<14377 15123 21439 23895 22640 22129>,
			<14440 15134 21546 23306 22746 22375>,
			<14465 15010 21580 21279 22615 22452>,
			<14449 14917 21564 20198 22368 22491>,
			<14298 14926 20431 20214 21500 22431>,
			<13821 14897 19095 20181 20780 22334>,
			<13431 14496 18228 19867 20539 22162>,
			<13162 14097 16004 19753 19736 20970>,
			<13021 13924 14973 19982 18142 17092>,
			<12950 13980 14828 19432 18424 16534>,
			<13047 13897 14757 18663 17635 15923>,
			<13240 14201 14960 18701 17158 15523>,
			<13358 14527 15409 18696 16577 15272>,
			<13580 14613 15645 18781 16648 15044>,
			<11827 14001 14678 19235 18656 16171>,
			<10074 11010 13619 20398 19500 16458>,
			<9085 9180 12349 21679 22337 21775>,
			<9085 9180 12349 21679 22337 21775>,
			<9085 9180 12349 21679 22337 21775>;
	};

	qcom,pc-temp-y6-lut {
		qcom,lut-col-legend = <(-10) 0 10 25 40 50>;
		qcom,lut-row-legend = <10000 9800 9600 9400 9200 9000>,
			<8800 8600 8400 8200 8000 7800>,
			<7600 7400 7200 7000 6800 6600>,
			<6400 6200 6000 5800 5600 5400>,
			<5200 5000 4800 4600 4400 4200>,
			<4000 3800 3600 3400 3200 3000>,
			<2800 2600 2400 2200 2000 1800>,
			<1600 1400 1200 1000 900 800>,
			<700 600 500 400 300 200>,
			<100 0>;
		qcom,lut-data = <5933 5444 5220 5075 5033 5027>,
			<5940 5456 5231 5075 5033 5027>,
			<5944 5464 5237 5075 5034 5027>,
			<5944 5469 5240 5075 5034 5027>,
			<5942 5471 5242 5075 5034 5028>,
			<5939 5472 5242 5075 5035 5028>,
			<5932 5469 5239 5075 5035 5028>,
			<5920 5462 5234 5075 5036 5029>,
			<5907 5458 5230 5075 5036 5029>,
			<5889 5454 5227 5076 5037 5030>,
			<5879 5451 5225 5077 5038 5031>,
			<5880 5448 5225 5078 5039 5032>,
			<5883 5446 5225 5080 5041 5033>,
			<5880 5446 5226 5082 5043 5034>,
			<5849 5449 5228 5084 5045 5036>,
			<5812 5452 5232 5088 5048 5037>,
			<5788 5447 5237 5092 5050 5040>,
			<5766 5437 5241 5097 5053 5042>,
			<5750 5423 5239 5104 5058 5047>,
			<5738 5400 5225 5114 5067 5054>,
			<5728 5379 5208 5119 5072 5058>,
			<5716 5366 5191 5102 5060 5049>,
			<5704 5356 5176 5077 5043 5035>,
			<5700 5349 5169 5068 5036 5029>,
			<5709 5344 5164 5063 5032 5026>,
			<5722 5341 5161 5062 5030 5025>,
			<5738 5338 5160 5062 5031 5025>,
			<5760 5336 5159 5063 5031 5025>,
			<5785 5339 5157 5064 5033 5026>,
			<5815 5354 5155 5067 5035 5028>,
			<5848 5374 5154 5069 5038 5030>,
			<5883 5397 5157 5070 5041 5033>,
			<5919 5426 5162 5071 5045 5037>,
			<5955 5458 5168 5073 5046 5038>,
			<5992 5493 5180 5074 5046 5039>,
			<6029 5533 5193 5074 5046 5039>,
			<6064 5577 5210 5074 5042 5036>,
			<6096 5625 5231 5074 5036 5031>,
			<6125 5675 5253 5074 5036 5031>,
			<6151 5727 5277 5075 5037 5033>,
			<6175 5781 5303 5076 5038 5035>,
			<6196 5832 5327 5082 5040 5037>,
			<6215 5885 5354 5087 5041 5039>,
			<6243 5941 5391 5089 5034 5028>,
			<6287 6008 5438 5091 5033 5026>,
			<6353 6029 5442 5090 5040 5036>,
			<6371 6082 5487 5098 5049 5046>,
			<6459 6144 5542 5107 5059 5056>,
			<6588 6217 5612 5120 5069 5067>,
			<6799 6316 5696 5130 5073 5068>,
			<7314 6476 5798 5127 5057 5046>,
			<8953 6947 5930 5117 5046 5039>,
			<13511 9781 6206 5138 5051 5043>,
			<31031 24273 7263 5168 5061 5053>,
			<31031 24273 7263 5168 5061 5053>,
			<31031 24273 7263 5168 5061 5053>;
	};

};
